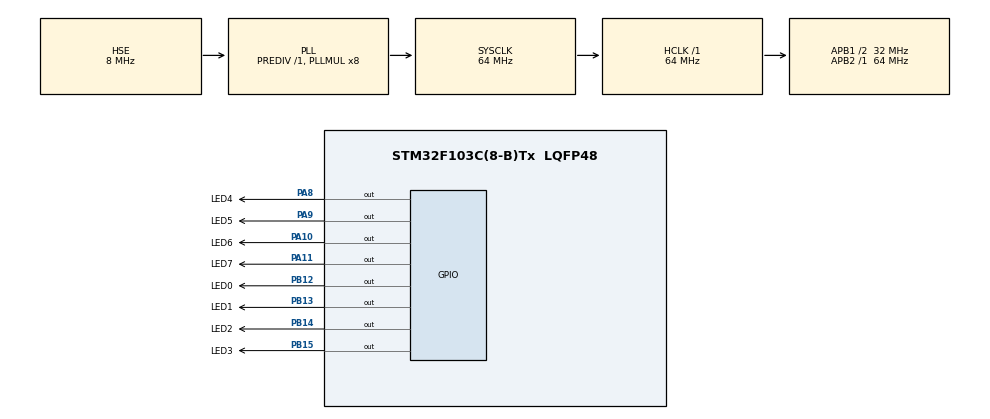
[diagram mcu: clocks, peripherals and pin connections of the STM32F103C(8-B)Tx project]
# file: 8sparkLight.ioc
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Mcu.Family=STM32F1
Mcu.Name=STM32F103C(8-B)Tx
Mcu.Package=LQFP48
NVIC.PriorityGroup=NVIC_PRIORITYGROUP_4
NVIC.TIM1_UP_IRQn=true\:0\:0\:false\:false\:true\:true\:true
PA10.GPIO_Label=LED6
PA10.GPIO_Speed=GPIO_SPEED_FREQ_HIGH
PA10.Signal=GPIO_Output
PA11.GPIO_Label=LED7
PA11.GPIO_Speed=GPIO_SPEED_FREQ_HIGH
PA11.Signal=GPIO_Output
PA13.Mode=Serial_Wire
PA13.Signal=SYS_JTMS-SWDIO
PA14.Mode=Serial_Wire
PA14.Signal=SYS_JTCK-SWCLK
PA8.GPIO_Label=LED4
PA8.Signal=GPIO_Output
PA9.GPIO_Label=LED5
PA9.GPIO_Speed=GPIO_SPEED_FREQ_HIGH
PA9.Signal=GPIO_Output
PB12.GPIO_Label=LED0
PB12.GPIO_Speed=GPIO_SPEED_FREQ_HIGH
PB12.Signal=GPIO_Output
PB13.GPIO_Label=LED1
PB13.GPIO_Speed=GPIO_SPEED_FREQ_HIGH
PB13.Signal=GPIO_Output
PB14.GPIO_Label=LED2
PB14.GPIO_Speed=GPIO_SPEED_FREQ_HIGH
PB14.Signal=GPIO_Output
PB15.GPIO_Label=LED3
PB15.GPIO_Speed=GPIO_SPEED_FREQ_HIGH
PB15.Signal=GPIO_Output
PD0-OSC_IN.Mode=HSE-External-Oscillator
PD0-OSC_IN.Signal=RCC_OSC_IN
PD1-OSC_OUT.Mode=HSE-External-Oscillator
PD1-OSC_OUT.Signal=RCC_OSC_OUT
ProjectManager.HeapSize=0x200
ProjectManager.StackSize=0x400
ProjectManager.TargetToolchain=MDK-ARM V5.27
RCC.AHBFreq_Value=64000000
RCC.APB1CLKDivider=RCC_HCLK_DIV2
RCC.APB1Freq_Value=32000000
RCC.APB1TimFreq_Value=64000000
RCC.APB2Freq_Value=64000000
RCC.APB2TimFreq_Value=64000000
RCC.HCLKFreq_Value=64000000
RCC.PLLMUL=RCC_PLL_MUL8
RCC.PLLSourceVirtual=RCC_PLLSOURCE_HSE
RCC.SYSCLKFreq_VALUE=64000000
RCC.SYSCLKSource=RCC_SYSCLKSOURCE_PLLCLK
RCC.USBFreq_Value=64000000
TIM1.Period=500
TIM1.Prescaler=64000
VP_TIM1_VS_ClockSourceINT.Mode=Internal
board=custom

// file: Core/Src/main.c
/* USER CODE BEGIN Header */
/**
  ******************************************************************************
  * @file           : main.c
  * @brief          : Main program body
  ******************************************************************************
  * @attention
  *
  * <h2><center>&copy; Copyright (c) 2020 STMicroelectronics.
  * All rights reserved.</center></h2>
  *
  * This software component is licensed by ST under BSD 3-Clause license,
  * the "License"; You may not use this file except in compliance with the
  * License. You may obtain a copy of the License at:
  *                        opensource.org/licenses/BSD-3-Clause
  *
  ******************************************************************************
  */
/* USER CODE END Header */
#include "main.h"

TIM_HandleTypeDef htim1;

void SystemClock_Config(void);
static void MX_GPIO_Init(void);
static void MX_TIM1_Init(void);

/* USER CODE BEGIN 0 */
void HAL_TIM_PeriodElapsedCallback(TIM_HandleTypeDef *htim)
{
	if(htim->Instance == TIM1){  // 每秒切换一次 每两秒亮一下 (64M / 64000 ) * 1000 = 1s
		HAL_GPIO_TogglePin(LED0_GPIO_Port, LED0_Pin);
		HAL_GPIO_TogglePin(LED1_GPIO_Port, LED1_Pin);
		HAL_GPIO_TogglePin(LED2_GPIO_Port, LED2_Pin);
		HAL_GPIO_TogglePin(LED3_GPIO_Port, LED3_Pin);
		HAL_GPIO_TogglePin(LED4_GPIO_Port, LED4_Pin);
		HAL_GPIO_TogglePin(LED5_GPIO_Port, LED5_Pin);
		HAL_GPIO_TogglePin(LED6_GPIO_Port, LED6_Pin);
		HAL_GPIO_TogglePin(LED7_GPIO_Port, LED7_Pin);
	}
}
/* USER CODE END 0 */

int main(void)
{

  /* MCU Configuration--------------------------------------------------------*/

  /* Reset of all peripherals, Initializes the Flash interface and the Systick. */
  HAL_Init();

  /* Configure the system clock */
  SystemClock_Config();

  /* Initialize all configured peripherals */
  MX_GPIO_Init();
  MX_TIM1_Init();
  /* USER CODE BEGIN 2 */
	HAL_TIM_Base_Start_IT(&htim1);
  /* USER CODE END 2 */

  /* Infinite loop */
  while (1)
  {

  }
}

void SystemClock_Config(void)
{
  RCC_OscInitTypeDef RCC_OscInitStruct = {0};
  RCC_ClkInitTypeDef RCC_ClkInitStruct = {0};

  /** Initializes the RCC Oscillators according to the specified parameters
  * in the RCC_OscInitTypeDef structure.
  */
  RCC_OscInitStruct.OscillatorType = RCC_OSCILLATORTYPE_HSE;
  RCC_OscInitStruct.HSEState = RCC_HSE_ON;
  RCC_OscInitStruct.HSEPredivValue = RCC_HSE_PREDIV_DIV1;
  RCC_OscInitStruct.HSIState = RCC_HSI_ON;
  RCC_OscInitStruct.PLL.PLLState = RCC_PLL_ON;
  RCC_OscInitStruct.PLL.PLLSource = RCC_PLLSOURCE_HSE;
  RCC_OscInitStruct.PLL.PLLMUL = RCC_PLL_MUL8;
  if (HAL_RCC_OscConfig(&RCC_OscInitStruct) != HAL_OK)
  {
    Error_Handler();
  }
  /** Initializes the CPU, AHB and APB buses clocks
  */
  RCC_ClkInitStruct.ClockType = RCC_CLOCKTYPE_HCLK|RCC_CLOCKTYPE_SYSCLK
                              |RCC_CLOCKTYPE_PCLK1|RCC_CLOCKTYPE_PCLK2;
  RCC_ClkInitStruct.SYSCLKSource = RCC_SYSCLKSOURCE_PLLCLK;
  RCC_ClkInitStruct.AHBCLKDivider = RCC_SYSCLK_DIV1;
  RCC_ClkInitStruct.APB1CLKDivider = RCC_HCLK_DIV2;
  RCC_ClkInitStruct.APB2CLKDivider = RCC_HCLK_DIV1;

  if (HAL_RCC_ClockConfig(&RCC_ClkInitStruct, FLASH_LATENCY_2) != HAL_OK)
  {
    Error_Handler();
  }
}

static void MX_TIM1_Init(void)
{

  TIM_ClockConfigTypeDef sClockSourceConfig = {0};
  TIM_MasterConfigTypeDef sMasterConfig = {0};

  htim1.Instance = TIM1;
  htim1.Init.Prescaler = 64000;
  htim1.Init.CounterMode = TIM_COUNTERMODE_UP;
  htim1.Init.Period = 1000;
  htim1.Init.ClockDivision = TIM_CLOCKDIVISION_DIV1;
  htim1.Init.RepetitionCounter = 0;
  htim1.Init.AutoReloadPreload = TIM_AUTORELOAD_PRELOAD_DISABLE;
  if (HAL_TIM_Base_Init(&htim1) != HAL_OK)
  {
    Error_Handler();
  }
  sClockSourceConfig.ClockSource = TIM_CLOCKSOURCE_INTERNAL;
  if (HAL_TIM_ConfigClockSource(&htim1, &sClockSourceConfig) != HAL_OK)
  {
    Error_Handler();
  }
  sMasterConfig.MasterOutputTrigger = TIM_TRGO_RESET;
  sMasterConfig.MasterSlaveMode = TIM_MASTERSLAVEMODE_DISABLE;
  if (HAL_TIMEx_MasterConfigSynchronization(&htim1, &sMasterConfig) != HAL_OK)
  {
    Error_Handler();
  }

}

static void MX_GPIO_Init(void)
{
  GPIO_InitTypeDef GPIO_InitStruct = {0};

  /* GPIO Ports Clock Enable */
  __HAL_RCC_GPIOD_CLK_ENABLE();
  __HAL_RCC_GPIOB_CLK_ENABLE();
  __HAL_RCC_GPIOA_CLK_ENABLE();

  /*Configure GPIO pin Output Level */
  HAL_GPIO_WritePin(GPIOB, LED0_Pin|LED1_Pin|LED2_Pin|LED3_Pin, GPIO_PIN_RESET);

  /*Configure GPIO pin Output Level */
  HAL_GPIO_WritePin(GPIOA, LED4_Pin|LED5_Pin|LED6_Pin|LED7_Pin, GPIO_PIN_RESET);

  /*Configure GPIO pins : LED0_Pin LED1_Pin LED2_Pin LED3_Pin */
  GPIO_InitStruct.Pin = LED0_Pin|LED1_Pin|LED2_Pin|LED3_Pin;
  GPIO_InitStruct.Mode = GPIO_MODE_OUTPUT_PP;
  GPIO_InitStruct.Pull = GPIO_NOPULL;
  GPIO_InitStruct.Speed = GPIO_SPEED_FREQ_HIGH;
  HAL_GPIO_Init(GPIOB, &GPIO_InitStruct);

  /*Configure GPIO pin : LED4_Pin */
  GPIO_InitStruct.Pin = LED4_Pin;
  GPIO_InitStruct.Mode = GPIO_MODE_OUTPUT_PP;
  GPIO_InitStruct.Pull = GPIO_NOPULL;
  GPIO_InitStruct.Speed = GPIO_SPEED_FREQ_LOW;
  HAL_GPIO_Init(LED4_GPIO_Port, &GPIO_InitStruct);

  /*Configure GPIO pins : LED5_Pin LED6_Pin LED7_Pin */
  GPIO_InitStruct.Pin = LED5_Pin|LED6_Pin|LED7_Pin;
  GPIO_InitStruct.Mode = GPIO_MODE_OUTPUT_PP;
  GPIO_InitStruct.Pull = GPIO_NOPULL;
  GPIO_InitStruct.Speed = GPIO_SPEED_FREQ_HIGH;
  HAL_GPIO_Init(GPIOA, &GPIO_InitStruct);

}

void Error_Handler(void)
{
}

/************************ (C) COPYRIGHT STMicroelectronics *****END OF FILE****/
